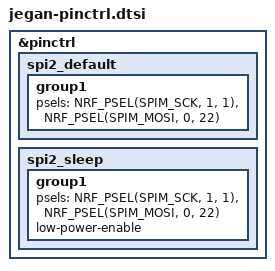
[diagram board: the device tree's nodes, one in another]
&pinctrl {

  /* spi2 for led strip */
  spi2_default: spi2_default {
    group1 {
      psels = <NRF_PSEL(SPIM_SCK, 1, 1)>,
              <NRF_PSEL(SPIM_MOSI, 0, 22)> ;
    };
  };

  spi2_sleep: spi2_sleep {
    group1 {
      psels = <NRF_PSEL(SPIM_SCK, 1, 1)>,
      <NRF_PSEL(SPIM_MOSI, 0, 22)> ;
      low-power-enable;
    };
  };
};
